# HDSC_HC32F4A0 register map
Vendor: HDSC Co.,Ltd.; Series: ARMCM4; File version: 1.0
CPU: CM4 r0p1, little endian, MPU, FPU, 4 interrupt priority bits
Registers are 32-bit, read-write, reset 0x0 unless marked. A register's access mark holds for its fields unless they carry their own. Offsets are from the block's base; [hi:lo] are bit positions; {n}, {i} and the like mark numbered series; 'fields as' and 'values as' point back to an identical list.

## USBF
Base 0x40080000
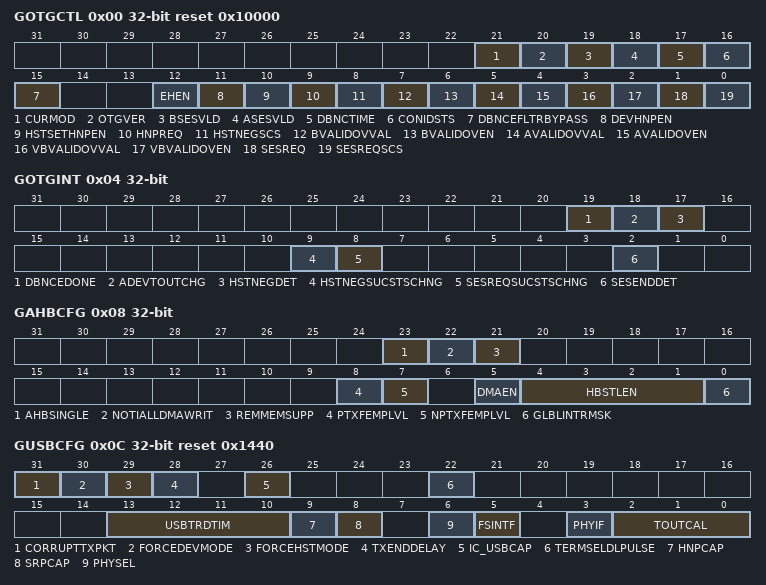
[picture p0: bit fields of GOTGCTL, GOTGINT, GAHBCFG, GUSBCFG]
0x00 GOTGCTL ro reset 0x10000
  [21] CURMOD, [20] OTGVER rw, [19] BSESVLD, [18] ASESVLD, [17] DBNCTIME, [16] CONIDSTS, [15] DBNCEFLTRBYPASS rw, [12] EHEN rw, [11] DEVHNPEN rw, [10] HSTSETHNPEN rw, [9] HNPREQ rw, [8] HSTNEGSCS, [7] BVALIDOVVAL rw, [6] BVALIDOVEN rw, [5] AVALIDOVVAL rw, [4] AVALIDOVEN rw, [3] VBVALIDOVVAL rw, [2] VBVALIDOVEN rw, [1] SESREQ rw, [0] SESREQSCS
0x04 GOTGINT
  [19] DBNCEDONE, [18] ADEVTOUTCHG, [17] HSTNEGDET, [9] HSTNEGSUCSTSCHNG, [8] SESREQSUCSTSCHNG, [2] SESENDDET
0x08 GAHBCFG
  [23] AHBSINGLE, [22] NOTIALLDMAWRIT, [21] REMMEMSUPP, [8] PTXFEMPLVL, [7] NPTXFEMPLVL, [5] DMAEN, [4:1] HBSTLEN, [0] GLBLINTRMSK
0x0C GUSBCFG reset 0x1440
  [31] CORRUPTTXPKT wo, [30] FORCEDEVMODE, [29] FORCEHSTMODE, [28] TXENDDELAY, [26] IC_USBCAP, [22] TERMSELDLPULSE, [13:10] USBTRDTIM, [9] HNPCAP, [8] SRPCAP, [6] PHYSEL, [5] FSINTF, [3] PHYIF, [2:0] TOUTCAL
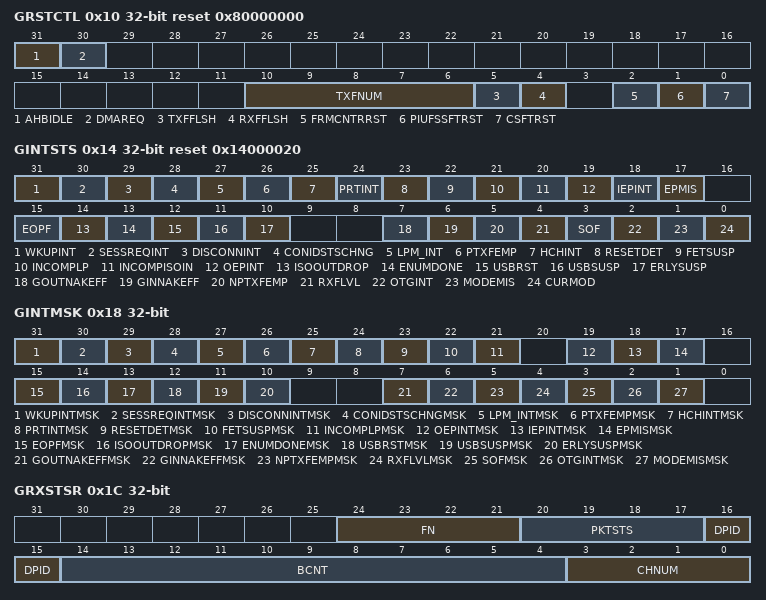
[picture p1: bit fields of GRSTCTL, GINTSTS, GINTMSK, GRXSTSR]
0x10 GRSTCTL reset 0x80000000
  [31] AHBIDLE ro, [30] DMAREQ ro, [10:6] TXFNUM, [5] TXFFLSH, [4] RXFFLSH, [2] FRMCNTRRST, [1] PIUFSSFTRST, [0] CSFTRST
0x14 GINTSTS ro reset 0x14000020
  [31] WKUPINT rw, [30] SESSREQINT rw, [29] DISCONNINT rw, [28] CONIDSTSCHNG rw, [27] LPM_INT rw, [26] PTXFEMP, [25] HCHINT, [24] PRTINT, [23] RESETDET rw, [22] FETSUSP rw, [21] INCOMPLP rw, [20] INCOMPISOIN rw, [19] OEPINT, [18] IEPINT, [17] EPMIS rw, [15] EOPF rw, [14] ISOOUTDROP rw, [13] ENUMDONE rw, [12] USBRST rw, [11] USBSUSP rw, [10] ERLYSUSP rw, [7] GOUTNAKEFF, [6] GINNAKEFF, [5] NPTXFEMP, [4] RXFLVL, [3] SOF rw, [2] OTGINT, [1] MODEMIS rw, [0] CURMOD
0x18 GINTMSK
  [31] WKUPINTMSK, [30] SESSREQINTMSK, [29] DISCONNINTMSK, [28] CONIDSTSCHNGMSK, [27] LPM_INTMSK, [26] PTXFEMPMSK, [25] HCHINTMSK, [24] PRTINTMSK, [23] RESETDETMSK, [22] FETSUSPMSK, [21] INCOMPLPMSK, [19] OEPINTMSK, [18] IEPINTMSK, [17] EPMISMSK, [15] EOPFMSK, [14] ISOOUTDROPMSK, [13] ENUMDONEMSK, [12] USBRSTMSK, [11] USBSUSPMSK, [10] ERLYSUSPMSK, [7] GOUTNAKEFFMSK, [6] GINNAKEFFMSK, [5] NPTXFEMPMSK, [4] RXFLVLMSK, [3] SOFMSK, [2] OTGINTMSK, [1] MODEMISMSK
0x1C GRXSTSR ro
  [24:21] FN, [20:17] PKTSTS, [16:15] DPID, [14:4] BCNT, [3:0] CHNUM
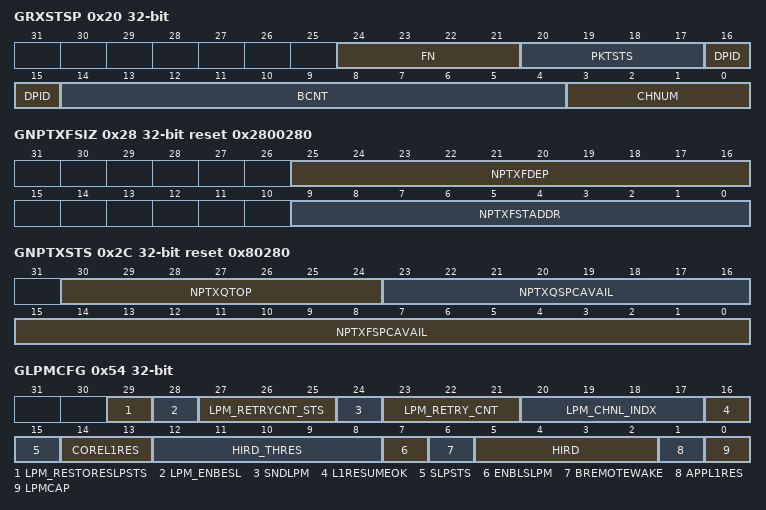
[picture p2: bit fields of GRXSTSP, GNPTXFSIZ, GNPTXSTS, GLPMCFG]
0x20 GRXSTSP ro
  [24:21] FN, [20:17] PKTSTS, [16:15] DPID, [14:4] BCNT, [3:0] CHNUM
0x24 GRXFSIZ reset 0x280
  [9:0] RXFDEP
0x28 GNPTXFSIZ reset 0x2800280
  [25:16] NPTXFDEP, [9:0] NPTXFSTADDR
0x2C GNPTXSTS ro reset 0x80280
  [30:24] NPTXQTOP, [23:16] NPTXQSPCAVAIL, [15:0] NPTXFSPCAVAIL
0x3C GUID reset 0x12345678
0x54 GLPMCFG
  [29] LPM_RESTORESLPSTS, [28] LPM_ENBESL, [27:25] LPM_RETRYCNT_STS ro, [24] SNDLPM, [23:21] LPM_RETRY_CNT, [20:17] LPM_CHNL_INDX, [16] L1RESUMEOK ro, [15] SLPSTS ro, [14:13] COREL1RES ro, [12:8] HIRD_THRES, [7] ENBLSLPM, [6] BREMOTEWAKE, [5:2] HIRD, [1] APPL1RES, [0] LPMCAP
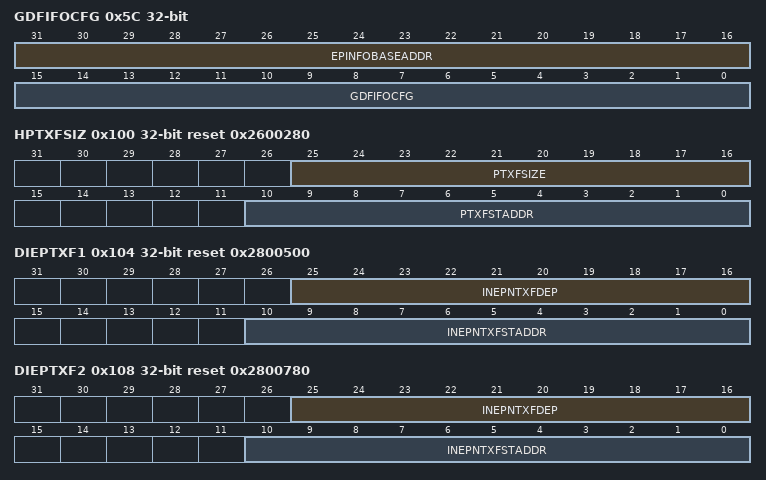
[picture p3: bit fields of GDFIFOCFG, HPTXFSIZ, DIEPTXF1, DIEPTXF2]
0x5C GDFIFOCFG
  [31:16] EPINFOBASEADDR, [15:0] GDFIFOCFG
0x100 HPTXFSIZ reset 0x2600280
  [25:16] PTXFSIZE, [10:0] PTXFSTADDR
0x104 DIEPTXF1 reset 0x2800500
  [25:16] INEPNTXFDEP, [10:0] INEPNTXFSTADDR
0x108 DIEPTXF2 reset 0x2800780
  [25:16] INEPNTXFDEP, [10:0] INEPNTXFSTADDR
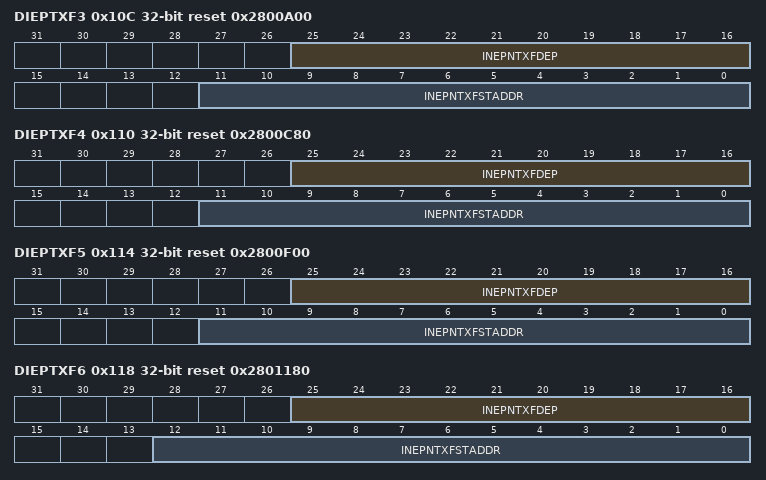
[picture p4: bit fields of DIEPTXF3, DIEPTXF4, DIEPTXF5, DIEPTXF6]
0x10C DIEPTXF3 reset 0x2800A00
  [25:16] INEPNTXFDEP, [11:0] INEPNTXFSTADDR
0x110 DIEPTXF4 reset 0x2800C80
  [25:16] INEPNTXFDEP, [11:0] INEPNTXFSTADDR
0x114 DIEPTXF5 reset 0x2800F00
  [25:16] INEPNTXFDEP, [11:0] INEPNTXFSTADDR
0x118 DIEPTXF6 reset 0x2801180
  [25:16] INEPNTXFDEP, [12:0] INEPNTXFSTADDR
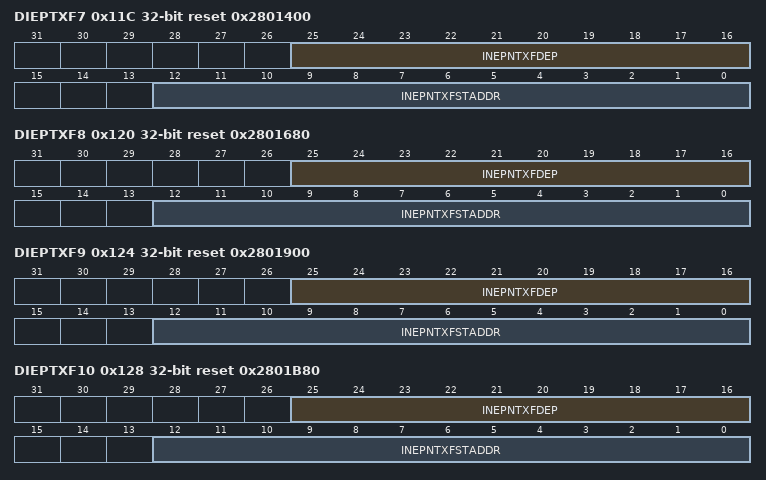
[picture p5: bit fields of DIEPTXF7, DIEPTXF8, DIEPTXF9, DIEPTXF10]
0x11C DIEPTXF7 reset 0x2801400
  [25:16] INEPNTXFDEP, [12:0] INEPNTXFSTADDR
0x120 DIEPTXF8 reset 0x2801680
  [25:16] INEPNTXFDEP, [12:0] INEPNTXFSTADDR
0x124 DIEPTXF9 reset 0x2801900
  [25:16] INEPNTXFDEP, [12:0] INEPNTXFSTADDR
0x128 DIEPTXF10 reset 0x2801B80
  [25:16] INEPNTXFDEP, [12:0] INEPNTXFSTADDR
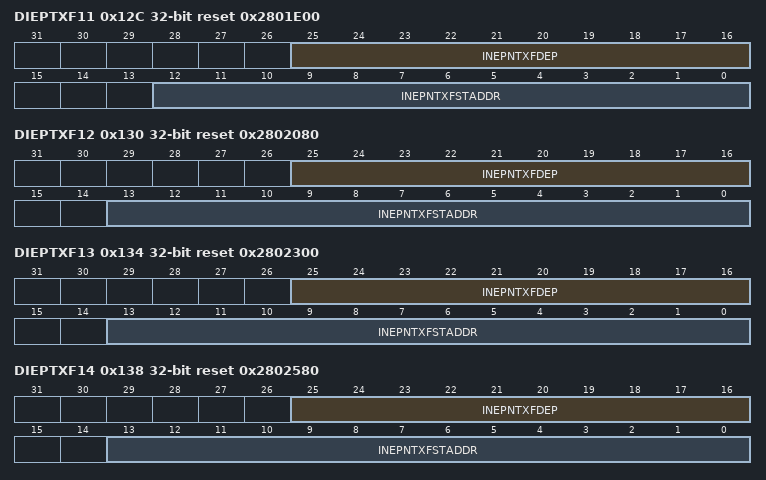
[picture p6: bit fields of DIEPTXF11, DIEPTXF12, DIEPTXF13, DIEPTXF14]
0x12C DIEPTXF11 reset 0x2801E00
  [25:16] INEPNTXFDEP, [12:0] INEPNTXFSTADDR
0x130 DIEPTXF12 reset 0x2802080
  [25:16] INEPNTXFDEP, [13:0] INEPNTXFSTADDR
0x134 DIEPTXF13 reset 0x2802300
  [25:16] INEPNTXFDEP, [13:0] INEPNTXFSTADDR
0x138 DIEPTXF14 reset 0x2802580
  [25:16] INEPNTXFDEP, [13:0] INEPNTXFSTADDR
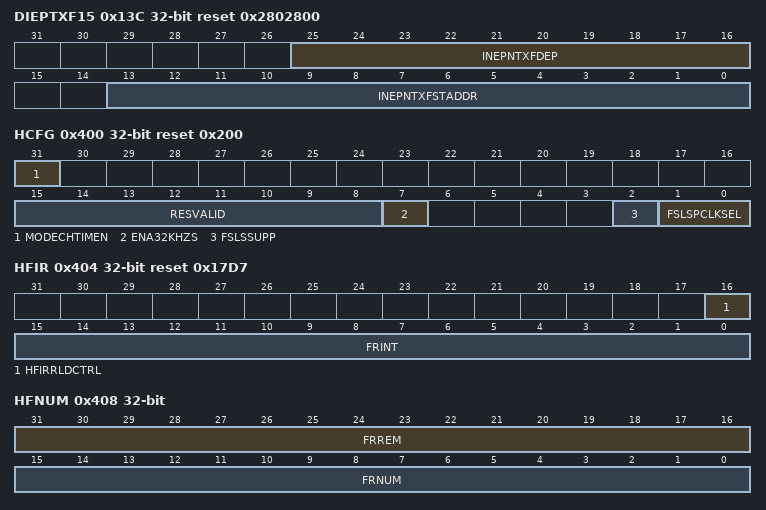
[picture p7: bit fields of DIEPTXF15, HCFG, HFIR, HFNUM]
0x13C DIEPTXF15 reset 0x2802800
  [25:16] INEPNTXFDEP, [13:0] INEPNTXFSTADDR
0x400 HCFG reset 0x200
  [31] MODECHTIMEN, [15:8] RESVALID, [7] ENA32KHZS, [2] FSLSSUPP, [1:0] FSLSPCLKSEL
0x404 HFIR reset 0x17D7
  [16] HFIRRLDCTRL, [15:0] FRINT
0x408 HFNUM ro
  [31:16] FRREM, [15:0] FRNUM
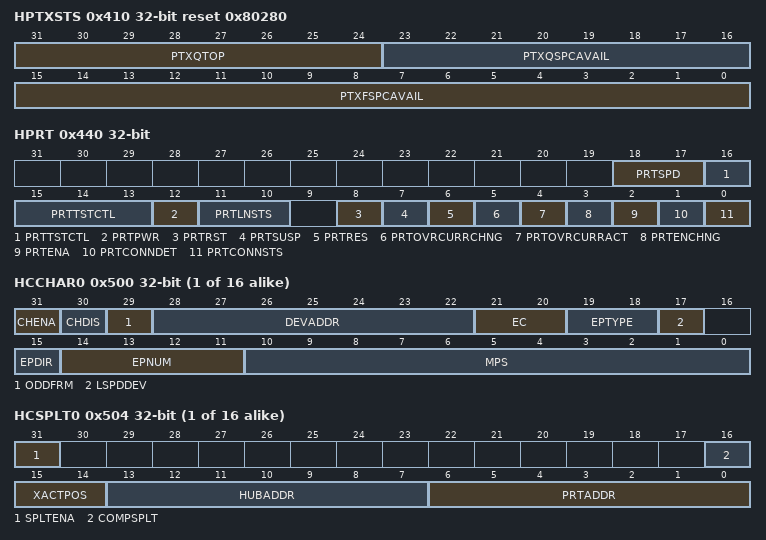
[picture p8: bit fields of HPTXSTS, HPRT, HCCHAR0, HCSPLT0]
0x410 HPTXSTS ro reset 0x80280
  [31:24] PTXQTOP, [23:16] PTXQSPCAVAIL, [15:0] PTXFSPCAVAIL
0x414 HAINT ro
  [15:0] HAINT
0x418 HAINTMSK
  [15:0] HAINTMSK
0x440 HPRT ro
  [18:17] PRTSPD, [16:13] PRTTSTCTL rw, [12] PRTPWR rw, [11:10] PRTLNSTS, [8] PRTRST rw, [7] PRTSUSP rw, [6] PRTRES rw, [5] PRTOVRCURRCHNG rw, [4] PRTOVRCURRACT, [3] PRTENCHNG rw, [2] PRTENA rw, [1] PRTCONNDET rw, [0] PRTCONNSTS
{0x500+0x20*i} HCCHAR{i} (i=0..15)
  [31] CHENA, [30] CHDIS, [29] ODDFRM, [28:22] DEVADDR, [21:20] EC, [19:18] EPTYPE, [17] LSPDDEV, [15] EPDIR, [14:11] EPNUM, [10:0] MPS
{0x504+0x20*i} HCSPLT{i} (i=0..15)
  [31] SPLTENA, [16] COMPSPLT, [15:14] XACTPOS, [13:7] HUBADDR, [6:0] PRTADDR
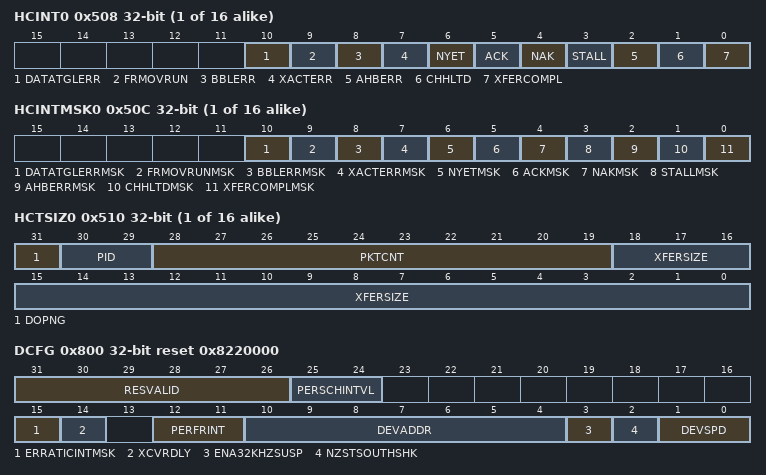
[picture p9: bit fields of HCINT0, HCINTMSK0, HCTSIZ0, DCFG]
{0x508+0x20*i} HCINT{i} (i=0..15)
  [10] DATATGLERR, [9] FRMOVRUN, [8] BBLERR, [7] XACTERR, [6] NYET, [5] ACK, [4] NAK, [3] STALL, [2] AHBERR, [1] CHHLTD, [0] XFERCOMPL
{0x50C+0x20*i} HCINTMSK{i} (i=0..15)
  [10] DATATGLERRMSK, [9] FRMOVRUNMSK, [8] BBLERRMSK, [7] XACTERRMSK, [6] NYETMSK, [5] ACKMSK, [4] NAKMSK, [3] STALLMSK, [2] AHBERRMSK, [1] CHHLTDMSK, [0] XFERCOMPLMSK
{0x510+0x20*i} HCTSIZ{i} (i=0..15)
  [31] DOPNG, [30:29] PID, [28:19] PKTCNT, [18:0] XFERSIZE
{0x514+0x20*i} HCDMA{i} (i=0..15)
0x800 DCFG reset 0x8220000
  [31:26] RESVALID, [25:24] PERSCHINTVL, [15] ERRATICINTMSK, [14] XCVRDLY, [12:11] PERFRINT, [10:4] DEVADDR, [3] ENA32KHZSUSP, [2] NZSTSOUTHSHK, [1:0] DEVSPD
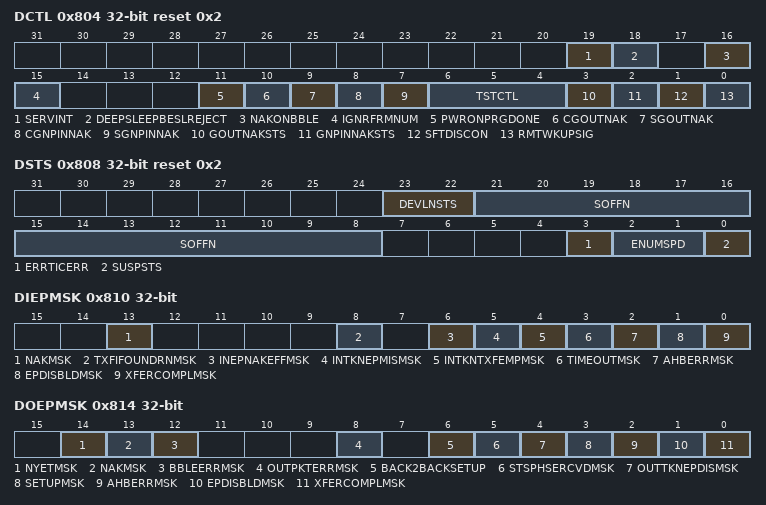
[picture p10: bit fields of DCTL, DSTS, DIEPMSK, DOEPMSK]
0x804 DCTL reset 0x2
  [19] SERVINT, [18] DEEPSLEEPBESLREJECT, [16] NAKONBBLE, [15] IGNRFRMNUM, [11] PWRONPRGDONE, [10] CGOUTNAK wo, [9] SGOUTNAK wo, [8] CGNPINNAK wo, [7] SGNPINNAK wo, [6:4] TSTCTL, [3] GOUTNAKSTS ro, [2] GNPINNAKSTS ro, [1] SFTDISCON, [0] RMTWKUPSIG
0x808 DSTS ro reset 0x2
  [23:22] DEVLNSTS, [21:8] SOFFN, [3] ERRTICERR, [2:1] ENUMSPD, [0] SUSPSTS
0x810 DIEPMSK
  [13] NAKMSK, [8] TXFIFOUNDRNMSK, [6] INEPNAKEFFMSK, [5] INTKNEPMISMSK, [4] INTKNTXFEMPMSK, [3] TIMEOUTMSK, [2] AHBERRMSK, [1] EPDISBLDMSK, [0] XFERCOMPLMSK
0x814 DOEPMSK
  [14] NYETMSK, [13] NAKMSK, [12] BBLEERRMSK, [8] OUTPKTERRMSK, [6] BACK2BACKSETUP, [5] STSPHSERCVDMSK, [4] OUTTKNEPDISMSK, [3] SETUPMSK, [2] AHBERRMSK, [1] EPDISBLDMSK, [0] XFERCOMPLMSK
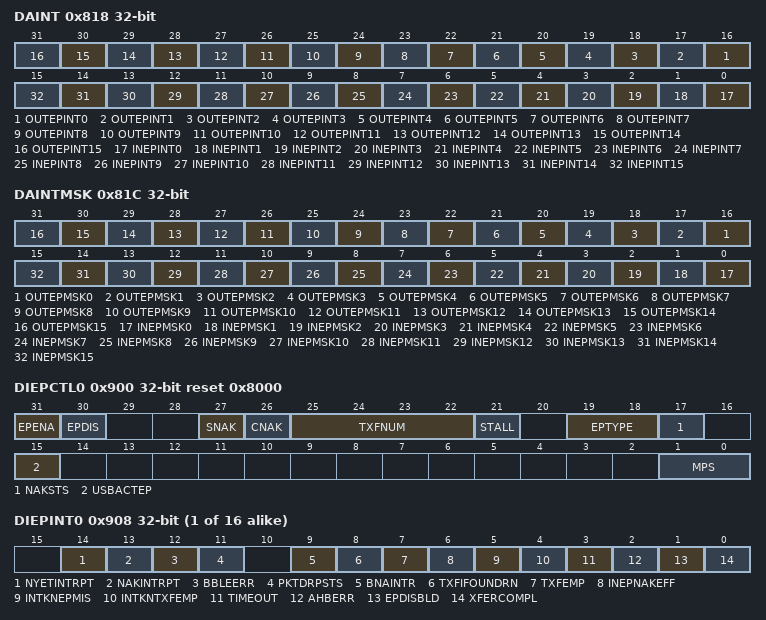
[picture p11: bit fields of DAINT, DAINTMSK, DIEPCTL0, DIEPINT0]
0x818 DAINT ro
  [n+16] OUTEPINT{n} (n=0..15), [n] INEPINT{n} (n=0..15)
0x81C DAINTMSK
  [n+16] OUTEPMSK{n} (n=0..15), [n] INEPMSK{n} (n=0..15)
0x834 DIEPEMPMSK
  [15:0] INEPTXFEMPMSK
0x900 DIEPCTL0 reset 0x8000
  [31] EPENA, [30] EPDIS, [27] SNAK wo, [26] CNAK wo, [25:22] TXFNUM, [21] STALL, [19:18] EPTYPE ro, [17] NAKSTS ro, [15] USBACTEP ro, [1:0] MPS
{0x908+0x20*i} DIEPINT{i} (i=0..15)
  [14] NYETINTRPT, [13] NAKINTRPT, [12] BBLEERR, [11] PKTDRPSTS, [9] BNAINTR, [8] TXFIFOUNDRN, [7] TXFEMP ro, [6] INEPNAKEFF, [5] INTKNEPMIS, [4] INTKNTXFEMP, [3] TIMEOUT, [2] AHBERR, [1] EPDISBLD, [0] XFERCOMPL
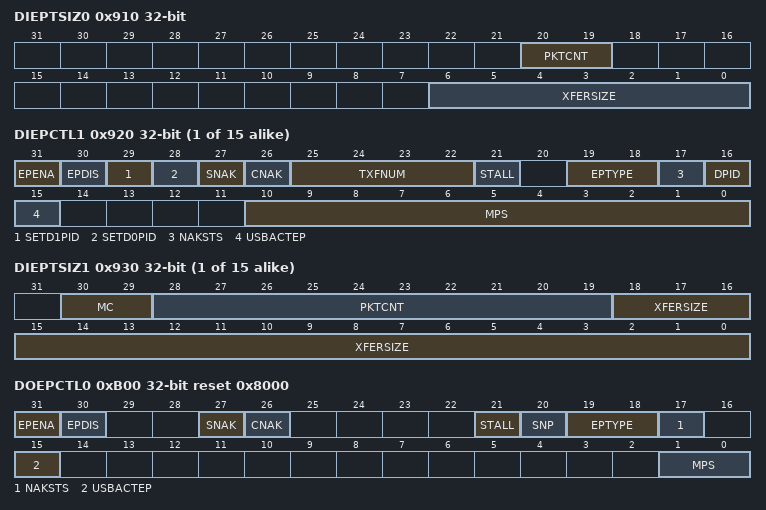
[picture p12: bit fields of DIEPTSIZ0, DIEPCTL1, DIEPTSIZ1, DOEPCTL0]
0x910 DIEPTSIZ0
  [20:19] PKTCNT, [6:0] XFERSIZE
0x914 DIEPDMA0
0x918 DTXFSTS0 ro reset 0x280
  [15:0] INEPTXFSPCAVAIL
{0x900+0x20*i} DIEPCTL{i} (i=1..15)
  [31] EPENA, [30] EPDIS, [29] SETD1PID wo, [28] SETD0PID wo, [27] SNAK wo, [26] CNAK wo, [25:22] TXFNUM, [21] STALL, [19:18] EPTYPE, [17] NAKSTS ro, [16] DPID ro, [15] USBACTEP, [10:0] MPS
{0x910+0x20*i} DIEPTSIZ{i} (i=1..15)
  [30:29] MC, [28:19] PKTCNT, [18:0] XFERSIZE
{0x914+0x20*i} DIEPDMA{i} reset 0x280 (i=1..15)
{0x918+0x20*i} DTXFSTS{i} ro (i=1..15)
  [15:0] INEPTXFSPCAVAIL
0xB00 DOEPCTL0 ro reset 0x8000
  [31] EPENA rw, [30] EPDIS, [27] SNAK wo, [26] CNAK wo, [21] STALL rw, [20] SNP rw, [19:18] EPTYPE, [17] NAKSTS, [15] USBACTEP, [1:0] MPS
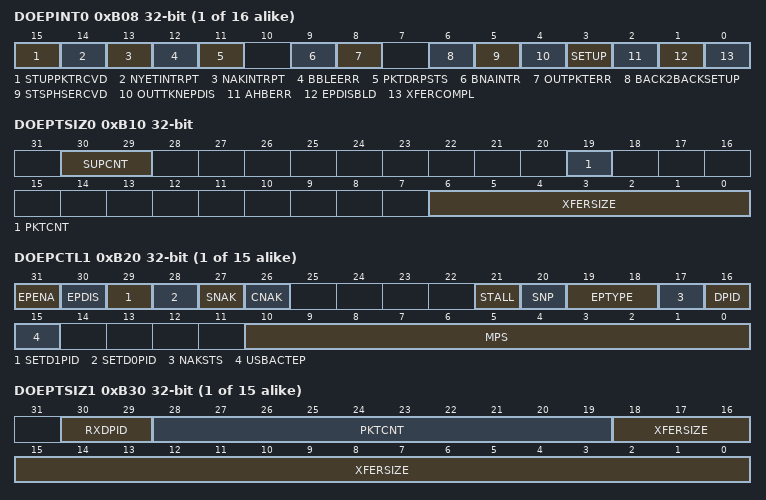
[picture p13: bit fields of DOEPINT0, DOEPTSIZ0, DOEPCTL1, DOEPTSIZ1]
{0xB08+0x20*i} DOEPINT{i} (i=0..15)
  [15] STUPPKTRCVD, [14] NYETINTRPT, [13] NAKINTRPT, [12] BBLEERR, [11] PKTDRPSTS, [9] BNAINTR, [8] OUTPKTERR, [6] BACK2BACKSETUP, [5] STSPHSERCVD, [4] OUTTKNEPDIS, [3] SETUP, [2] AHBERR, [1] EPDISBLD, [0] XFERCOMPL
0xB10 DOEPTSIZ0
  [30:29] SUPCNT, [19] PKTCNT, [6:0] XFERSIZE
{0xB14+0x20*i} DOEPDMA{i} (i=0..15)
{0xB00+0x20*i} DOEPCTL{i} (i=1..15)
  [31] EPENA, [30] EPDIS, [29] SETD1PID wo, [28] SETD0PID wo, [27] SNAK wo, [26] CNAK wo, [21] STALL, [20] SNP, [19:18] EPTYPE, [17] NAKSTS ro, [16] DPID ro, [15] USBACTEP, [10:0] MPS
{0xB10+0x20*i} DOEPTSIZ{i} (i=1..15)
  [30:29] RXDPID ro, [28:19] PKTCNT, [18:0] XFERSIZE
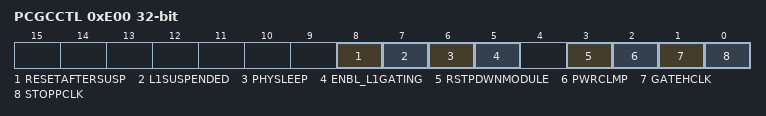
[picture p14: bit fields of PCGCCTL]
0xE00 PCGCCTL
  [8] RESETAFTERSUSP, [7] L1SUSPENDED ro, [6] PHYSLEEP ro, [5] ENBL_L1GATING, [3] RSTPDWNMODULE, [2] PWRCLMP, [1] GATEHCLK, [0] STOPPCLK

## USBH
Base 0x400C0000
Registers as USBF; these are added or differ:
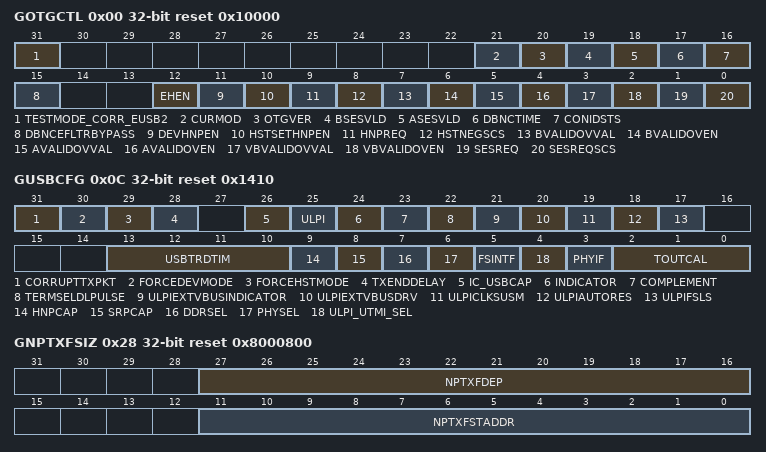
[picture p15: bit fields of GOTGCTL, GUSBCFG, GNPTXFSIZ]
0x00 GOTGCTL ro reset 0x10000
  [31] TESTMODE_CORR_EUSB2 rw, [21] CURMOD, [20] OTGVER rw, [19] BSESVLD, [18] ASESVLD, [17] DBNCTIME, [16] CONIDSTS, [15] DBNCEFLTRBYPASS rw, [12] EHEN rw, [11] DEVHNPEN rw, [10] HSTSETHNPEN rw, [9] HNPREQ rw, [8] HSTNEGSCS, [7] BVALIDOVVAL rw, [6] BVALIDOVEN rw, [5] AVALIDOVVAL rw, [4] AVALIDOVEN rw, [3] VBVALIDOVVAL rw, [2] VBVALIDOVEN rw, [1] SESREQ rw, [0] SESREQSCS
0x0C GUSBCFG reset 0x1410
  [31] CORRUPTTXPKT wo, [30] FORCEDEVMODE, [29] FORCEHSTMODE, [28] TXENDDELAY, [26] IC_USBCAP, [25] ULPI, [24] INDICATOR, [23] COMPLEMENT, [22] TERMSELDLPULSE, [21] ULPIEXTVBUSINDICATOR, [20] ULPIEXTVBUSDRV, [19] ULPICLKSUSM, [18] ULPIAUTORES, [17] ULPIFSLS, [13:10] USBTRDTIM, [9] HNPCAP, [8] SRPCAP, [7] DDRSEL, [6] PHYSEL, [5] FSINTF, [4] ULPI_UTMI_SEL, [3] PHYIF, [2:0] TOUTCAL
0x24 GRXFSIZ reset 0x800
  [11:0] RXFDEP
0x28 GNPTXFSIZ reset 0x8000800
  [27:16] NPTXFDEP, [11:0] NPTXFSTADDR
0x2C GNPTXSTS ro reset 0x8000800
  [30:24] NPTXQTOP, [23:16] NPTXQSPCAVAIL, [15:0] NPTXFSPCAVAIL
0x34 GPVNDCTL
  [27] VSTSDONE, [26] VSTSBSY ro, [25] NEWREGREQ, [22] REGWR, [21:16] REGADDR, [15:8] VCTRL, [7:0] REGDATA
0x5C GDFIFOCFG reset 0x7E00800
  [31:16] EPINFOBASEADDR, [15:0] GDFIFOCFG
0x100 HPTXFSIZ
  [27:16] PTXFSIZE, [12:0] PTXFSTADDR
0x104 DIEPTXF1 reset 0x8001000
  [27:16] INEPNTXFDEP, [12:0] INEPNTXFSTADDR
0x108 DIEPTXF2 reset 0x8001800
  [27:16] INEPNTXFDEP, [12:0] INEPNTXFSTADDR
0x10C DIEPTXF3 reset 0x8002000
  [27:16] INEPNTXFDEP, [13:0] INEPNTXFSTADDR
0x110 DIEPTXF4 reset 0x8002800
  [27:16] INEPNTXFDEP, [13:0] INEPNTXFSTADDR
0x114 DIEPTXF5 reset 0x8003000
  [27:16] INEPNTXFDEP, [13:0] INEPNTXFSTADDR
0x118 DIEPTXF6 reset 0x8003800
  [27:16] INEPNTXFDEP, [13:0] INEPNTXFSTADDR
0x11C DIEPTXF7 reset 0x8004000
  [27:16] INEPNTXFDEP, [14:0] INEPNTXFSTADDR
0x120 DIEPTXF8 reset 0x8004800
  [27:16] INEPNTXFDEP, [14:0] INEPNTXFSTADDR
0x124 DIEPTXF9 reset 0x8005000
  [27:16] INEPNTXFDEP, [14:0] INEPNTXFSTADDR
0x128 DIEPTXF10 reset 0x8005800
  [27:16] INEPNTXFDEP, [14:0] INEPNTXFSTADDR
0x12C DIEPTXF11 reset 0x8006000
  [27:16] INEPNTXFDEP, [14:0] INEPNTXFSTADDR
0x130 DIEPTXF12 reset 0x8006800
  [27:16] INEPNTXFDEP, [14:0] INEPNTXFSTADDR
0x134 DIEPTXF13 reset 0x8007000
  [27:16] INEPNTXFDEP, [14:0] INEPNTXFSTADDR
0x138 DIEPTXF14 reset 0x8007800
  [27:16] INEPNTXFDEP, [14:0] INEPNTXFSTADDR
0x13C DIEPTXF15 reset 0x8008000
  [27:16] INEPNTXFDEP, [15:0] INEPNTXFSTADDR
0x400 HCFG reset 0x220000
  [31] MODECHTIMEN, [15:8] RESVALID, [7] ENA32KHZS, [2] FSLSSUPP, [1:0] FSLSPCLKSEL
0x410 HPTXSTS ro
  [31:24] PTXQTOP, [23:16] PTXQSPCAVAIL, [15:0] PTXFSPCAVAIL
0x800 DCFG reset 0x8220000
  [31:26] RESVALID, [25:24] PERSCHINTVL, [17] IPGISOCSUPT, [15] ERRATICINTMSK, [14] XCVRDLY, [12:11] PERFRINT, [10:4] DEVADDR, [3] ENA32KHZSUSP, [2] NZSTSOUTHSHK, [1:0] DEVSPD
0x830 DTHRCTL reset 0x1C100020
  [27] ARBPRKEN, [25:17] RXTHRLEN, [16] RXTHREN, [12:11] AHBTHRRATIO, [10:2] TXTHRLEN, [1] ISOTHREN, [0] NONISOTHREN
0x838 DEACHINT ro
  [31:16] ECHOUTEPINT, [15:0] ECHINEPINT
0x83C DEACHINTMSK
  [n+16] ECHOUTEPMSK{n} (n=0..15), [n] ECHINEPMSK{n} (n=0..15)
0x844 DIEPEACHMSK1
  [13] NAKMSK, [8] TXFIFOUNDRNMSK, [6] INEPNAKEFFMSK, [5] INTKNEPMISMSK, [4] INTKNTXFEMPMSK, [3] TIMEOUTMSK, [2] AHBERRMSK, [1] EPDISBLDMSK, [0] XFERCOMPLMSK
0x884 DOEPEACHMSK1
  [14] NYETMSK, [13] NAKMSK, [12] BBLEERRMSK, [8] OUTPKTERRMSK, [6] BACK2BACKSETUP, [5] STSPHSRCVDMSK, [4] OUTTKNEPDISMSK, [3] SETUPMSK, [2] AHBERRMSK, [1] EPDISBLDMSK, [0] XFERCOMPLMSK
{0x908+0x20*i} DIEPINT{i} reset 0x80 (i=0..15)
  fields as USBF.DIEPINT0
{0x918+0x20*i} DTXFSTS{i} ro reset 0x800 (i=0..15)
  [15:0] INEPTXFSPCAVAIL
{0x914+0x20*i} DIEPDMA{i} (i=1..15)
